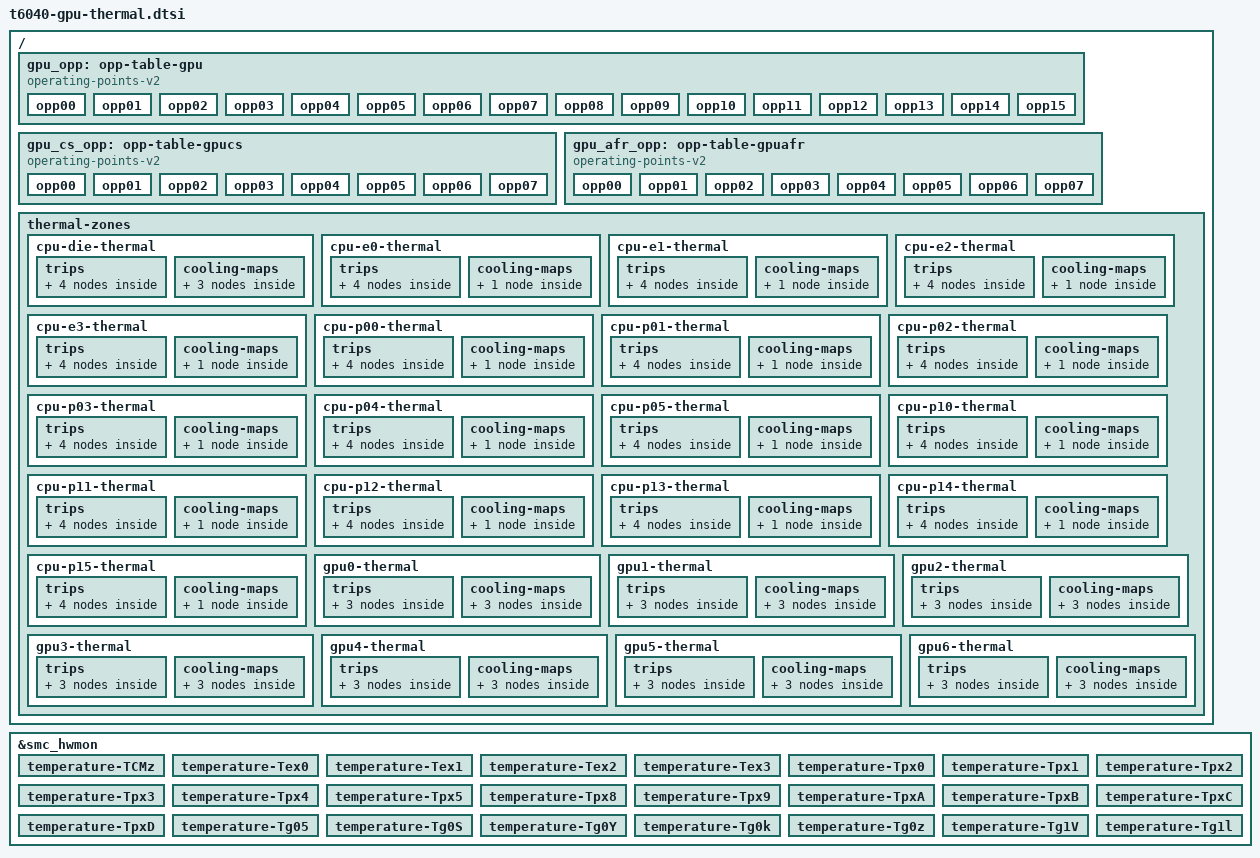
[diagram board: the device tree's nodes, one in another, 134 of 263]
// SPDX-License-Identifier: GPL-2.0+ OR MIT
/*
 * GPU operating points and thermal zones of the T6040 Macs, with the SMC
 * sensors the zones read. Shared by the J614s, J616s and J773s.
 *
 * Copyright The Asahi Linux Contributors
 */

#include <dt-bindings/thermal/thermal.h>

/ {
	/*
	 * GPU performance states, one opp-microvolt cell per cluster (ADT
	 * /arm-io/sgx perf-states and perf-states1). The operating points are
	 * binned per device: the loader fills these placeholders.
	 * The driver requires a completed calibration handoff. Entries keep the
	 * order of the GPU performance states, which is not sorted by frequency.
	 */
	gpu_opp: opp-table-gpu {
		compatible = "operating-points-v2";

		opp00 {
			opp-hz = /bits/ 64 <0>;
			opp-microvolt = <0 0>;
		};
		opp01 {
			opp-hz = /bits/ 64 <0>;
			opp-microvolt = <0 0>;
		};
		opp02 {
			opp-hz = /bits/ 64 <0>;
			opp-microvolt = <0 0>;
		};
		opp03 {
			opp-hz = /bits/ 64 <0>;
			opp-microvolt = <0 0>;
		};
		opp04 {
			opp-hz = /bits/ 64 <0>;
			opp-microvolt = <0 0>;
		};
		opp05 {
			opp-hz = /bits/ 64 <0>;
			opp-microvolt = <0 0>;
		};
		opp06 {
			opp-hz = /bits/ 64 <0>;
			opp-microvolt = <0 0>;
		};
		opp07 {
			opp-hz = /bits/ 64 <0>;
			opp-microvolt = <0 0>;
		};
		opp08 {
			opp-hz = /bits/ 64 <0>;
			opp-microvolt = <0 0>;
		};
		opp09 {
			opp-hz = /bits/ 64 <0>;
			opp-microvolt = <0 0>;
		};
		opp10 {
			opp-hz = /bits/ 64 <0>;
			opp-microvolt = <0 0>;
		};
		opp11 {
			opp-hz = /bits/ 64 <0>;
			opp-microvolt = <0 0>;
		};
		opp12 {
			opp-hz = /bits/ 64 <0>;
			opp-microvolt = <0 0>;
		};
		opp13 {
			opp-hz = /bits/ 64 <0>;
			opp-microvolt = <0 0>;
		};
		opp14 {
			opp-hz = /bits/ 64 <0>;
			opp-microvolt = <0 0>;
		};
		opp15 {
			opp-hz = /bits/ 64 <0>;
			opp-microvolt = <0 0>;
		};
	};

	/* The GPU's CS clock domain (ADT cs-perf-states) */
	gpu_cs_opp: opp-table-gpucs {
		compatible = "operating-points-v2";

		opp00 {
			opp-hz = /bits/ 64 <0>;
			opp-microvolt = <0>;
		};
		opp01 {
			opp-hz = /bits/ 64 <0>;
			opp-microvolt = <0>;
		};
		opp02 {
			opp-hz = /bits/ 64 <0>;
			opp-microvolt = <0>;
		};
		opp03 {
			opp-hz = /bits/ 64 <0>;
			opp-microvolt = <0>;
		};
		opp04 {
			opp-hz = /bits/ 64 <0>;
			opp-microvolt = <0>;
		};
		opp05 {
			opp-hz = /bits/ 64 <0>;
			opp-microvolt = <0>;
		};
		opp06 {
			opp-hz = /bits/ 64 <0>;
			opp-microvolt = <0>;
		};
		opp07 {
			opp-hz = /bits/ 64 <0>;
			opp-microvolt = <0>;
		};
	};

	/* The GPU's AFR clock domain (ADT afr-perf-states) */
	gpu_afr_opp: opp-table-gpuafr {
		compatible = "operating-points-v2";

		opp00 {
			opp-hz = /bits/ 64 <0>;
			opp-microvolt = <0>;
		};
		opp01 {
			opp-hz = /bits/ 64 <0>;
			opp-microvolt = <0>;
		};
		opp02 {
			opp-hz = /bits/ 64 <0>;
			opp-microvolt = <0>;
		};
		opp03 {
			opp-hz = /bits/ 64 <0>;
			opp-microvolt = <0>;
		};
		opp04 {
			opp-hz = /bits/ 64 <0>;
			opp-microvolt = <0>;
		};
		opp05 {
			opp-hz = /bits/ 64 <0>;
			opp-microvolt = <0>;
		};
		opp06 {
			opp-hz = /bits/ 64 <0>;
			opp-microvolt = <0>;
		};
		opp07 {
			opp-hz = /bits/ 64 <0>;
			opp-microvolt = <0>;
		};
	};

	/*
	 * Zones on the SMC die-maximum sensors (smc_hwmon 0-23): TCMz for the
	 * die, Tex0-3, Tpx0-5 and Tpx8-D per CPU cluster, and the seven
	 * hottest GPU sensors. The PMP's loop holds the die at the ADT
	 * fast-die-ctrl-loop target of 110 C, as on macOS; these zones are
	 * the backstop behind it.
	 *
	 * - CPU zones run the power allocator from 75 C, control at 115 C and
	 *   throttle only the cluster their sensor sits on. The 1 s samples
	 *   jump by about 10 C, so the zones are integral-led.
	 * - GPU zones: the GPU firmware limits itself from 101 C; these shed
	 *   CPU power from the same point (on at 90 C) and shut down at 118 C
	 *   after three samples, as the CPU zones do. A powered-off GPU reads
	 *   -4 to 4 C.
	 * - Hot at 120 C only reports; critical is the ADT's 125 C sochot
	 *   level, after three samples (critical-samples).
	 * - The fans stay with the SMC, as on macOS: no active trips.
	 *
	 * sustainable-power is the J616s's: a 720 s all-core load held TCMz
	 * at 112-114 C with P0 25.3 W, P1 23.9 W and E 2.1 W on the SMC core
	 * rails. The J614s and J773s inherit these values until measured.
	 */
	thermal-zones {
		cpu-die-thermal {
			polling-delay-passive = <1000>;
			polling-delay = <1000>;
			integral-time-constant-ms = <20000>;
			critical-samples = <3>;
			sustainable-power = <51300>;
			thermal-sensors = <&smc_hwmon 0>;	/* TCMz */

			trips {
				cpu_die_switch_on: cpu-die-switch-on {
					temperature = <75000>;
					hysteresis = <2000>;
					type = "passive";
				};

				cpu_die_passive: cpu-die-passive {
					temperature = <115000>;
					hysteresis = <5000>;
					type = "passive";
				};

				cpu-die-hot {
					temperature = <120000>;
					hysteresis = <2000>;
					type = "hot";
				};

				cpu-die-critical {
					temperature = <125000>;
					hysteresis = <0>;
					type = "critical";
				};
			};

			cooling-maps {
				map-e {
					trip = <&cpu_die_passive>;
					cooling-device =
						<&cpu_e0 THERMAL_NO_LIMIT THERMAL_NO_LIMIT>,
						<&cpu_e1 THERMAL_NO_LIMIT THERMAL_NO_LIMIT>,
						<&cpu_e2 THERMAL_NO_LIMIT THERMAL_NO_LIMIT>,
						<&cpu_e3 THERMAL_NO_LIMIT THERMAL_NO_LIMIT>;
				};

				map-p0 {
					trip = <&cpu_die_passive>;
					cooling-device =
						<&cpu_p00 THERMAL_NO_LIMIT THERMAL_NO_LIMIT>,
						<&cpu_p01 THERMAL_NO_LIMIT THERMAL_NO_LIMIT>,
						<&cpu_p02 THERMAL_NO_LIMIT THERMAL_NO_LIMIT>,
						<&cpu_p03 THERMAL_NO_LIMIT THERMAL_NO_LIMIT>,
						<&cpu_p04 THERMAL_NO_LIMIT THERMAL_NO_LIMIT>;
				};

				map-p1 {
					trip = <&cpu_die_passive>;
					cooling-device =
						<&cpu_p10 THERMAL_NO_LIMIT THERMAL_NO_LIMIT>,
						<&cpu_p11 THERMAL_NO_LIMIT THERMAL_NO_LIMIT>,
						<&cpu_p12 THERMAL_NO_LIMIT THERMAL_NO_LIMIT>,
						<&cpu_p13 THERMAL_NO_LIMIT THERMAL_NO_LIMIT>,
						<&cpu_p14 THERMAL_NO_LIMIT THERMAL_NO_LIMIT>;
				};
			};
		};

		cpu-e0-thermal {
			polling-delay-passive = <1000>;
			polling-delay = <1000>;
			integral-time-constant-ms = <20000>;
			critical-samples = <3>;
			sustainable-power = <2100>;
			thermal-sensors = <&smc_hwmon 1>;	/* Tex0 */

			trips {
				cpu_e0_switch_on: trip-switch-on {
					temperature = <75000>;
					hysteresis = <2000>;
					type = "passive";
				};

				cpu_e0_passive: trip-passive {
					temperature = <115000>;
					hysteresis = <5000>;
					type = "passive";
				};

				trip-hot {
					temperature = <120000>;
					hysteresis = <2000>;
					type = "hot";
				};

				trip-critical {
					temperature = <125000>;
					hysteresis = <0>;
					type = "critical";
				};
			};

			cooling-maps {
				map-e {
					trip = <&cpu_e0_passive>;
					cooling-device =
						<&cpu_e0 THERMAL_NO_LIMIT THERMAL_NO_LIMIT>,
						<&cpu_e1 THERMAL_NO_LIMIT THERMAL_NO_LIMIT>,
						<&cpu_e2 THERMAL_NO_LIMIT THERMAL_NO_LIMIT>,
						<&cpu_e3 THERMAL_NO_LIMIT THERMAL_NO_LIMIT>;
				};
			};
		};

		cpu-e1-thermal {
			polling-delay-passive = <1000>;
			polling-delay = <1000>;
			integral-time-constant-ms = <20000>;
			critical-samples = <3>;
			sustainable-power = <2100>;
			thermal-sensors = <&smc_hwmon 2>;	/* Tex1 */

			trips {
				cpu_e1_switch_on: trip-switch-on {
					temperature = <75000>;
					hysteresis = <2000>;
					type = "passive";
				};

				cpu_e1_passive: trip-passive {
					temperature = <115000>;
					hysteresis = <5000>;
					type = "passive";
				};

				trip-hot {
					temperature = <120000>;
					hysteresis = <2000>;
					type = "hot";
				};

				trip-critical {
					temperature = <125000>;
					hysteresis = <0>;
					type = "critical";
				};
			};

			cooling-maps {
				map-e {
					trip = <&cpu_e1_passive>;
					cooling-device =
						<&cpu_e0 THERMAL_NO_LIMIT THERMAL_NO_LIMIT>,
						<&cpu_e1 THERMAL_NO_LIMIT THERMAL_NO_LIMIT>,
						<&cpu_e2 THERMAL_NO_LIMIT THERMAL_NO_LIMIT>,
						<&cpu_e3 THERMAL_NO_LIMIT THERMAL_NO_LIMIT>;
				};
			};
		};

		cpu-e2-thermal {
			polling-delay-passive = <1000>;
			polling-delay = <1000>;
			integral-time-constant-ms = <20000>;
			critical-samples = <3>;
			sustainable-power = <2100>;
			thermal-sensors = <&smc_hwmon 3>;	/* Tex2 */

			trips {
				cpu_e2_switch_on: trip-switch-on {
					temperature = <75000>;
					hysteresis = <2000>;
					type = "passive";
				};

				cpu_e2_passive: trip-passive {
					temperature = <115000>;
					hysteresis = <5000>;
					type = "passive";
				};

				trip-hot {
					temperature = <120000>;
					hysteresis = <2000>;
					type = "hot";
				};

				trip-critical {
					temperature = <125000>;
					hysteresis = <0>;
					type = "critical";
				};
			};

			cooling-maps {
				map-e {
					trip = <&cpu_e2_passive>;
					cooling-device =
						<&cpu_e0 THERMAL_NO_LIMIT THERMAL_NO_LIMIT>,
						<&cpu_e1 THERMAL_NO_LIMIT THERMAL_NO_LIMIT>,
						<&cpu_e2 THERMAL_NO_LIMIT THERMAL_NO_LIMIT>,
						<&cpu_e3 THERMAL_NO_LIMIT THERMAL_NO_LIMIT>;
				};
			};
		};

		cpu-e3-thermal {
			polling-delay-passive = <1000>;
			polling-delay = <1000>;
			integral-time-constant-ms = <20000>;
			critical-samples = <3>;
			sustainable-power = <2100>;
			thermal-sensors = <&smc_hwmon 4>;	/* Tex3 */

			trips {
				cpu_e3_switch_on: trip-switch-on {
					temperature = <75000>;
					hysteresis = <2000>;
					type = "passive";
				};

				cpu_e3_passive: trip-passive {
					temperature = <115000>;
					hysteresis = <5000>;
					type = "passive";
				};

				trip-hot {
					temperature = <120000>;
					hysteresis = <2000>;
					type = "hot";
				};

				trip-critical {
					temperature = <125000>;
					hysteresis = <0>;
					type = "critical";
				};
			};

			cooling-maps {
				map-e {
					trip = <&cpu_e3_passive>;
					cooling-device =
						<&cpu_e0 THERMAL_NO_LIMIT THERMAL_NO_LIMIT>,
						<&cpu_e1 THERMAL_NO_LIMIT THERMAL_NO_LIMIT>,
						<&cpu_e2 THERMAL_NO_LIMIT THERMAL_NO_LIMIT>,
						<&cpu_e3 THERMAL_NO_LIMIT THERMAL_NO_LIMIT>;
				};
			};
		};

		cpu-p00-thermal {
			polling-delay-passive = <1000>;
			polling-delay = <1000>;
			integral-time-constant-ms = <20000>;
			critical-samples = <3>;
			sustainable-power = <25300>;
			thermal-sensors = <&smc_hwmon 5>;	/* Tpx0 */

			trips {
				cpu_p00_switch_on: trip-switch-on {
					temperature = <75000>;
					hysteresis = <2000>;
					type = "passive";
				};

				cpu_p00_passive: trip-passive {
					temperature = <115000>;
					hysteresis = <5000>;
					type = "passive";
				};

				trip-hot {
					temperature = <120000>;
					hysteresis = <2000>;
					type = "hot";
				};

				trip-critical {
					temperature = <125000>;
					hysteresis = <0>;
					type = "critical";
				};
			};

			cooling-maps {
				map-p0 {
					trip = <&cpu_p00_passive>;
					cooling-device =
						<&cpu_p00 THERMAL_NO_LIMIT THERMAL_NO_LIMIT>,
						<&cpu_p01 THERMAL_NO_LIMIT THERMAL_NO_LIMIT>,
						<&cpu_p02 THERMAL_NO_LIMIT THERMAL_NO_LIMIT>,
						<&cpu_p03 THERMAL_NO_LIMIT THERMAL_NO_LIMIT>,
						<&cpu_p04 THERMAL_NO_LIMIT THERMAL_NO_LIMIT>;
				};
			};
		};

		cpu-p01-thermal {
			polling-delay-passive = <1000>;
			polling-delay = <1000>;
			integral-time-constant-ms = <20000>;
			critical-samples = <3>;
			sustainable-power = <25300>;
			thermal-sensors = <&smc_hwmon 6>;	/* Tpx1 */

			trips {
				cpu_p01_switch_on: trip-switch-on {
					temperature = <75000>;
					hysteresis = <2000>;
					type = "passive";
				};

				cpu_p01_passive: trip-passive {
					temperature = <115000>;
					hysteresis = <5000>;
					type = "passive";
				};

				trip-hot {
					temperature = <120000>;
					hysteresis = <2000>;
					type = "hot";
				};

				trip-critical {
					temperature = <125000>;
					hysteresis = <0>;
					type = "critical";
				};
			};

			cooling-maps {
				map-p0 {
					trip = <&cpu_p01_passive>;
					cooling-device =
						<&cpu_p00 THERMAL_NO_LIMIT THERMAL_NO_LIMIT>,
						<&cpu_p01 THERMAL_NO_LIMIT THERMAL_NO_LIMIT>,
						<&cpu_p02 THERMAL_NO_LIMIT THERMAL_NO_LIMIT>,
						<&cpu_p03 THERMAL_NO_LIMIT THERMAL_NO_LIMIT>,
						<&cpu_p04 THERMAL_NO_LIMIT THERMAL_NO_LIMIT>;
				};
			};
		};

		cpu-p02-thermal {
			polling-delay-passive = <1000>;
			polling-delay = <1000>;
			integral-time-constant-ms = <20000>;
			critical-samples = <3>;
			sustainable-power = <25300>;
			thermal-sensors = <&smc_hwmon 7>;	/* Tpx2 */

			trips {
				cpu_p02_switch_on: trip-switch-on {
					temperature = <75000>;
					hysteresis = <2000>;
					type = "passive";
				};

				cpu_p02_passive: trip-passive {
					temperature = <115000>;
					hysteresis = <5000>;
					type = "passive";
				};

				trip-hot {
					temperature = <120000>;
					hysteresis = <2000>;
					type = "hot";
				};

				trip-critical {
					temperature = <125000>;
					hysteresis = <0>;
					type = "critical";
				};
			};

			cooling-maps {
				map-p0 {
					trip = <&cpu_p02_passive>;
					cooling-device =
						<&cpu_p00 THERMAL_NO_LIMIT THERMAL_NO_LIMIT>,
						<&cpu_p01 THERMAL_NO_LIMIT THERMAL_NO_LIMIT>,
						<&cpu_p02 THERMAL_NO_LIMIT THERMAL_NO_LIMIT>,
						<&cpu_p03 THERMAL_NO_LIMIT THERMAL_NO_LIMIT>,
						<&cpu_p04 THERMAL_NO_LIMIT THERMAL_NO_LIMIT>;
				};
			};
		};

		cpu-p03-thermal {
			polling-delay-passive = <1000>;
			polling-delay = <1000>;
			integral-time-constant-ms = <20000>;
			critical-samples = <3>;
			sustainable-power = <25300>;
			thermal-sensors = <&smc_hwmon 8>;	/* Tpx3 */

			trips {
				cpu_p03_switch_on: trip-switch-on {
					temperature = <75000>;
					hysteresis = <2000>;
					type = "passive";
				};

				cpu_p03_passive: trip-passive {
					temperature = <115000>;
					hysteresis = <5000>;
					type = "passive";
				};

				trip-hot {
					temperature = <120000>;
					hysteresis = <2000>;
					type = "hot";
				};

				trip-critical {
					temperature = <125000>;
					hysteresis = <0>;
					type = "critical";
				};
			};

			cooling-maps {
				map-p0 {
					trip = <&cpu_p03_passive>;
					cooling-device =
						<&cpu_p00 THERMAL_NO_LIMIT THERMAL_NO_LIMIT>,
						<&cpu_p01 THERMAL_NO_LIMIT THERMAL_NO_LIMIT>,
						<&cpu_p02 THERMAL_NO_LIMIT THERMAL_NO_LIMIT>,
						<&cpu_p03 THERMAL_NO_LIMIT THERMAL_NO_LIMIT>,
						<&cpu_p04 THERMAL_NO_LIMIT THERMAL_NO_LIMIT>;
				};
			};
		};

		cpu-p04-thermal {
			polling-delay-passive = <1000>;
			polling-delay = <1000>;
			integral-time-constant-ms = <20000>;
			critical-samples = <3>;
			sustainable-power = <25300>;
			thermal-sensors = <&smc_hwmon 9>;	/* Tpx4 */

			trips {
				cpu_p04_switch_on: trip-switch-on {
					temperature = <75000>;
					hysteresis = <2000>;
					type = "passive";
				};

				cpu_p04_passive: trip-passive {
					temperature = <115000>;
					hysteresis = <5000>;
					type = "passive";
				};

				trip-hot {
					temperature = <120000>;
					hysteresis = <2000>;
					type = "hot";
				};

				trip-critical {
					temperature = <125000>;
					hysteresis = <0>;
					type = "critical";
				};
			};

			cooling-maps {
				map-p0 {
					trip = <&cpu_p04_passive>;
					cooling-device =
						<&cpu_p00 THERMAL_NO_LIMIT THERMAL_NO_LIMIT>,
						<&cpu_p01 THERMAL_NO_LIMIT THERMAL_NO_LIMIT>,
						<&cpu_p02 THERMAL_NO_LIMIT THERMAL_NO_LIMIT>,
						<&cpu_p03 THERMAL_NO_LIMIT THERMAL_NO_LIMIT>,
						<&cpu_p04 THERMAL_NO_LIMIT THERMAL_NO_LIMIT>;
				};
			};
		};

		cpu-p05-thermal {
			polling-delay-passive = <1000>;
			polling-delay = <1000>;
			integral-time-constant-ms = <20000>;
			critical-samples = <3>;
			sustainable-power = <25300>;
			thermal-sensors = <&smc_hwmon 10>;	/* Tpx5 */

			trips {
				cpu_p05_switch_on: trip-switch-on {
					temperature = <75000>;
					hysteresis = <2000>;
					type = "passive";
				};

				cpu_p05_passive: trip-passive {
					temperature = <115000>;
					hysteresis = <5000>;
					type = "passive";
				};

				trip-hot {
					temperature = <120000>;
					hysteresis = <2000>;
					type = "hot";
				};

				trip-critical {
					temperature = <125000>;
					hysteresis = <0>;
					type = "critical";
				};
			};

			cooling-maps {
				map-p0 {
					trip = <&cpu_p05_passive>;
					cooling-device =
						<&cpu_p00 THERMAL_NO_LIMIT THERMAL_NO_LIMIT>,
						<&cpu_p01 THERMAL_NO_LIMIT THERMAL_NO_LIMIT>,
						<&cpu_p02 THERMAL_NO_LIMIT THERMAL_NO_LIMIT>,
						<&cpu_p03 THERMAL_NO_LIMIT THERMAL_NO_LIMIT>,
						<&cpu_p04 THERMAL_NO_LIMIT THERMAL_NO_LIMIT>;
				};
			};
		};

		cpu-p10-thermal {
			polling-delay-passive = <1000>;
			polling-delay = <1000>;
			integral-time-constant-ms = <20000>;
			critical-samples = <3>;
			sustainable-power = <23900>;
			thermal-sensors = <&smc_hwmon 11>;	/* Tpx8 */

			trips {
				cpu_p10_switch_on: trip-switch-on {
					temperature = <75000>;
					hysteresis = <2000>;
					type = "passive";
				};

				cpu_p10_passive: trip-passive {
					temperature = <115000>;
					hysteresis = <5000>;
					type = "passive";
				};

				trip-hot {
					temperature = <120000>;
					hysteresis = <2000>;
					type = "hot";
				};

				trip-critical {
					temperature = <125000>;
					hysteresis = <0>;
					type = "critical";
				};
			};

			cooling-maps {
				map-p1 {
					trip = <&cpu_p10_passive>;
					cooling-device =
						<&cpu_p10 THERMAL_NO_LIMIT THERMAL_NO_LIMIT>,
						<&cpu_p11 THERMAL_NO_LIMIT THERMAL_NO_LIMIT>,
						<&cpu_p12 THERMAL_NO_LIMIT THERMAL_NO_LIMIT>,
						<&cpu_p13 THERMAL_NO_LIMIT THERMAL_NO_LIMIT>,
						<&cpu_p14 THERMAL_NO_LIMIT THERMAL_NO_LIMIT>;
				};
			};
		};

		cpu-p11-thermal {
			polling-delay-passive = <1000>;
			polling-delay = <1000>;
			integral-time-constant-ms = <20000>;
			critical-samples = <3>;
			sustainable-power = <23900>;
			thermal-sensors = <&smc_hwmon 12>;	/* Tpx9 */

			trips {
				cpu_p11_switch_on: trip-switch-on {
					temperature = <75000>;
					hysteresis = <2000>;
					type = "passive";
				};

				cpu_p11_passive: trip-passive {
					temperature = <115000>;
					hysteresis = <5000>;
					type = "passive";
				};

				trip-hot {
					temperature = <120000>;
					hysteresis = <2000>;
					type = "hot";
				};

				trip-critical {
					temperature = <125000>;
					hysteresis = <0>;
					type = "critical";
				};
			};

			cooling-maps {
				map-p1 {
					trip = <&cpu_p11_passive>;
					cooling-device =
						<&cpu_p10 THERMAL_NO_LIMIT THERMAL_NO_LIMIT>,
						<&cpu_p11 THERMAL_NO_LIMIT THERMAL_NO_LIMIT>,
						<&cpu_p12 THERMAL_NO_LIMIT THERMAL_NO_LIMIT>,
						<&cpu_p13 THERMAL_NO_LIMIT THERMAL_NO_LIMIT>,
						<&cpu_p14 THERMAL_NO_LIMIT THERMAL_NO_LIMIT>;
				};
			};
		};

		cpu-p12-thermal {
			polling-delay-passive = <1000>;
			polling-delay = <1000>;
			integral-time-constant-ms = <20000>;
			critical-samples = <3>;
			sustainable-power = <23900>;
			thermal-sensors = <&smc_hwmon 13>;	/* TpxA */

			trips {
				cpu_p12_switch_on: trip-switch-on {
					temperature = <75000>;
					hysteresis = <2000>;
					type = "passive";
				};

				cpu_p12_passive: trip-passive {
					temperature = <115000>;
					hysteresis = <5000>;
					type = "passive";
				};

				trip-hot {
					temperature = <120000>;
					hysteresis = <2000>;
					type = "hot";
				};

				trip-critical {
					temperature = <125000>;
					hysteresis = <0>;
					type = "critical";
				};
			};

			cooling-maps {
				map-p1 {
					trip = <&cpu_p12_passive>;
					cooling-device =
						<&cpu_p10 THERMAL_NO_LIMIT THERMAL_NO_LIMIT>,
						<&cpu_p11 THERMAL_NO_LIMIT THERMAL_NO_LIMIT>,
						<&cpu_p12 THERMAL_NO_LIMIT THERMAL_NO_LIMIT>,
						<&cpu_p13 THERMAL_NO_LIMIT THERMAL_NO_LIMIT>,
						<&cpu_p14 THERMAL_NO_LIMIT THERMAL_NO_LIMIT>;
				};
			};
		};

		cpu-p13-thermal {
			polling-delay-passive = <1000>;
			polling-delay = <1000>;
			integral-time-constant-ms = <20000>;
			critical-samples = <3>;
			sustainable-power = <23900>;
			thermal-sensors = <&smc_hwmon 14>;	/* TpxB */

			trips {
				cpu_p13_switch_on: trip-switch-on {
					temperature = <75000>;
					hysteresis = <2000>;
					type = "passive";
				};

				cpu_p13_passive: trip-passive {
					temperature = <115000>;
					hysteresis = <5000>;
					type = "passive";
				};

				trip-hot {
					temperature = <120000>;
					hysteresis = <2000>;
					type = "hot";
				};

				trip-critical {
					temperature = <125000>;
					hysteresis = <0>;
					type = "critical";
				};
			};

			cooling-maps {
				map-p1 {
					trip = <&cpu_p13_passive>;
					cooling-device =
						<&cpu_p10 THERMAL_NO_LIMIT THERMAL_NO_LIMIT>,
						<&cpu_p11 THERMAL_NO_LIMIT THERMAL_NO_LIMIT>,
						<&cpu_p12 THERMAL_NO_LIMIT THERMAL_NO_LIMIT>,
						<&cpu_p13 THERMAL_NO_LIMIT THERMAL_NO_LIMIT>,
						<&cpu_p14 THERMAL_NO_LIMIT THERMAL_NO_LIMIT>;
				};
			};
		};

		cpu-p14-thermal {
			polling-delay-passive = <1000>;
			polling-delay = <1000>;
			integral-time-constant-ms = <20000>;
			critical-samples = <3>;
			sustainable-power = <23900>;
			thermal-sensors = <&smc_hwmon 15>;	/* TpxC */

			trips {
				cpu_p14_switch_on: trip-switch-on {
					temperature = <75000>;
					hysteresis = <2000>;
					type = "passive";
				};

				cpu_p14_passive: trip-passive {
					temperature = <115000>;
					hysteresis = <5000>;
					type = "passive";
				};

				trip-hot {
					temperature = <120000>;
					hysteresis = <2000>;
					type = "hot";
				};

				trip-critical {
					temperature = <125000>;
					hysteresis = <0>;
					type = "critical";
				};
			};

			cooling-maps {
				map-p1 {
					trip = <&cpu_p14_passive>;
					cooling-device =
						<&cpu_p10 THERMAL_NO_LIMIT THERMAL_NO_LIMIT>,
						<&cpu_p11 THERMAL_NO_LIMIT THERMAL_NO_LIMIT>,
						<&cpu_p12 THERMAL_NO_LIMIT THERMAL_NO_LIMIT>,
						<&cpu_p13 THERMAL_NO_LIMIT THERMAL_NO_LIMIT>,
						<&cpu_p14 THERMAL_NO_LIMIT THERMAL_NO_LIMIT>;
				};
			};
		};

		cpu-p15-thermal {
			polling-delay-passive = <1000>;
			polling-delay = <1000>;
			integral-time-constant-ms = <20000>;
			critical-samples = <3>;
			sustainable-power = <23900>;
			thermal-sensors = <&smc_hwmon 16>;	/* TpxD */

			trips {
				cpu_p15_switch_on: trip-switch-on {
					temperature = <75000>;
					hysteresis = <2000>;
					type = "passive";
				};

				cpu_p15_passive: trip-passive {
					temperature = <115000>;
					hysteresis = <5000>;
					type = "passive";
				};

				trip-hot {
					temperature = <120000>;
					hysteresis = <2000>;
					type = "hot";
				};

				trip-critical {
					temperature = <125000>;
					hysteresis = <0>;
					type = "critical";
				};
			};

			cooling-maps {
				map-p1 {
					trip = <&cpu_p15_passive>;
					cooling-device =
						<&cpu_p10 THERMAL_NO_LIMIT THERMAL_NO_LIMIT>,
						<&cpu_p11 THERMAL_NO_LIMIT THERMAL_NO_LIMIT>,
						<&cpu_p12 THERMAL_NO_LIMIT THERMAL_NO_LIMIT>,
						<&cpu_p13 THERMAL_NO_LIMIT THERMAL_NO_LIMIT>,
						<&cpu_p14 THERMAL_NO_LIMIT THERMAL_NO_LIMIT>;
				};
			};
		};

		gpu0-thermal {
			polling-delay-passive = <1000>;
			polling-delay = <1000>;
			critical-samples = <3>;
			sustainable-power = <51300>;
			thermal-sensors = <&smc_hwmon 17>;	/* Tg05 */

			trips {
				gpu0_switch_on: trip-switch-on {
					temperature = <90000>;
					hysteresis = <2000>;
					type = "passive";
				};

				gpu0_passive: trip-passive {
					temperature = <101000>;
					hysteresis = <5000>;
					type = "passive";
				};

				trip-critical {
					temperature = <118000>;
					hysteresis = <0>;
					type = "critical";
				};
			};

			cooling-maps {
				map-e {
					trip = <&gpu0_passive>;
					cooling-device =
						<&cpu_e0 THERMAL_NO_LIMIT THERMAL_NO_LIMIT>,
						<&cpu_e1 THERMAL_NO_LIMIT THERMAL_NO_LIMIT>,
						<&cpu_e2 THERMAL_NO_LIMIT THERMAL_NO_LIMIT>,
						<&cpu_e3 THERMAL_NO_LIMIT THERMAL_NO_LIMIT>;
				};

				map-p0 {
					trip = <&gpu0_passive>;
					cooling-device =
						<&cpu_p00 THERMAL_NO_LIMIT THERMAL_NO_LIMIT>,
						<&cpu_p01 THERMAL_NO_LIMIT THERMAL_NO_LIMIT>,
						<&cpu_p02 THERMAL_NO_LIMIT THERMAL_NO_LIMIT>,
						<&cpu_p03 THERMAL_NO_LIMIT THERMAL_NO_LIMIT>,
						<&cpu_p04 THERMAL_NO_LIMIT THERMAL_NO_LIMIT>;
				};

				map-p1 {
					trip = <&gpu0_passive>;
					cooling-device =
						<&cpu_p10 THERMAL_NO_LIMIT THERMAL_NO_LIMIT>,
						<&cpu_p11 THERMAL_NO_LIMIT THERMAL_NO_LIMIT>,
						<&cpu_p12 THERMAL_NO_LIMIT THERMAL_NO_LIMIT>,
						<&cpu_p13 THERMAL_NO_LIMIT THERMAL_NO_LIMIT>,
						<&cpu_p14 THERMAL_NO_LIMIT THERMAL_NO_LIMIT>;
				};
			};
		};

		gpu1-thermal {
			polling-delay-passive = <1000>;
			polling-delay = <1000>;
			critical-samples = <3>;
			sustainable-power = <51300>;
			thermal-sensors = <&smc_hwmon 18>;	/* Tg0S */

			trips {
				gpu1_switch_on: trip-switch-on {
					temperature = <90000>;
					hysteresis = <2000>;
					type = "passive";
				};

				gpu1_passive: trip-passive {
					temperature = <101000>;
					hysteresis = <5000>;
					type = "passive";
				};

				trip-critical {
					temperature = <118000>;
					hysteresis = <0>;
					type = "critical";
				};
			};

			cooling-maps {
				map-e {
					trip = <&gpu1_passive>;
					cooling-device =
						<&cpu_e0 THERMAL_NO_LIMIT THERMAL_NO_LIMIT>,
						<&cpu_e1 THERMAL_NO_LIMIT THERMAL_NO_LIMIT>,
						<&cpu_e2 THERMAL_NO_LIMIT THERMAL_NO_LIMIT>,
						<&cpu_e3 THERMAL_NO_LIMIT THERMAL_NO_LIMIT>;
				};

				map-p0 {
					trip = <&gpu1_passive>;
					cooling-device =
						<&cpu_p00 THERMAL_NO_LIMIT THERMAL_NO_LIMIT>,
						<&cpu_p01 THERMAL_NO_LIMIT THERMAL_NO_LIMIT>,
						<&cpu_p02 THERMAL_NO_LIMIT THERMAL_NO_LIMIT>,
						<&cpu_p03 THERMAL_NO_LIMIT THERMAL_NO_LIMIT>,
						<&cpu_p04 THERMAL_NO_LIMIT THERMAL_NO_LIMIT>;
				};

				map-p1 {
					trip = <&gpu1_passive>;
					cooling-device =
						<&cpu_p10 THERMAL_NO_LIMIT THERMAL_NO_LIMIT>,
						<&cpu_p11 THERMAL_NO_LIMIT THERMAL_NO_LIMIT>,
						<&cpu_p12 THERMAL_NO_LIMIT THERMAL_NO_LIMIT>,
						<&cpu_p13 THERMAL_NO_LIMIT THERMAL_NO_LIMIT>,
						<&cpu_p14 THERMAL_NO_LIMIT THERMAL_NO_LIMIT>;
				};
			};
		};

		gpu2-thermal {
			polling-delay-passive = <1000>;
			polling-delay = <1000>;
			critical-samples = <3>;
			sustainable-power = <51300>;
			thermal-sensors = <&smc_hwmon 19>;	/* Tg0Y */

			trips {
				gpu2_switch_on: trip-switch-on {
					temperature = <90000>;
					hysteresis = <2000>;
					type = "passive";
				};

				gpu2_passive: trip-passive {
					temperature = <101000>;
					hysteresis = <5000>;
					type = "passive";
				};

				trip-critical {
					temperature = <118000>;
					hysteresis = <0>;
					type = "critical";
				};
			};

			cooling-maps {
				map-e {
					trip = <&gpu2_passive>;
					cooling-device =
						<&cpu_e0 THERMAL_NO_LIMIT THERMAL_NO_LIMIT>,
						<&cpu_e1 THERMAL_NO_LIMIT THERMAL_NO_LIMIT>,
						<&cpu_e2 THERMAL_NO_LIMIT THERMAL_NO_LIMIT>,
						<&cpu_e3 THERMAL_NO_LIMIT THERMAL_NO_LIMIT>;
				};

				map-p0 {
					trip = <&gpu2_passive>;
					cooling-device =
						<&cpu_p00 THERMAL_NO_LIMIT THERMAL_NO_LIMIT>,
						<&cpu_p01 THERMAL_NO_LIMIT THERMAL_NO_LIMIT>,
						<&cpu_p02 THERMAL_NO_LIMIT THERMAL_NO_LIMIT>,
						<&cpu_p03 THERMAL_NO_LIMIT THERMAL_NO_LIMIT>,
						<&cpu_p04 THERMAL_NO_LIMIT THERMAL_NO_LIMIT>;
				};

				map-p1 {
					trip = <&gpu2_passive>;
					cooling-device =
						<&cpu_p10 THERMAL_NO_LIMIT THERMAL_NO_LIMIT>,
						<&cpu_p11 THERMAL_NO_LIMIT THERMAL_NO_LIMIT>,
						<&cpu_p12 THERMAL_NO_LIMIT THERMAL_NO_LIMIT>,
						<&cpu_p13 THERMAL_NO_LIMIT THERMAL_NO_LIMIT>,
						<&cpu_p14 THERMAL_NO_LIMIT THERMAL_NO_LIMIT>;
				};
			};
		};

		gpu3-thermal {
			polling-delay-passive = <1000>;
			polling-delay = <1000>;
			critical-samples = <3>;
			sustainable-power = <51300>;
			thermal-sensors = <&smc_hwmon 20>;	/* Tg0k */

			trips {
				gpu3_switch_on: trip-switch-on {
					temperature = <90000>;
					hysteresis = <2000>;
					type = "passive";
				};

				gpu3_passive: trip-passive {
					temperature = <101000>;
					hysteresis = <5000>;
					type = "passive";
				};

				trip-critical {
					temperature = <118000>;
					hysteresis = <0>;
					type = "critical";
				};
			};

			cooling-maps {
				map-e {
					trip = <&gpu3_passive>;
					cooling-device =
						<&cpu_e0 THERMAL_NO_LIMIT THERMAL_NO_LIMIT>,
						<&cpu_e1 THERMAL_NO_LIMIT THERMAL_NO_LIMIT>,
						<&cpu_e2 THERMAL_NO_LIMIT THERMAL_NO_LIMIT>,
						<&cpu_e3 THERMAL_NO_LIMIT THERMAL_NO_LIMIT>;
				};

				map-p0 {
					trip = <&gpu3_passive>;
					cooling-device =
						<&cpu_p00 THERMAL_NO_LIMIT THERMAL_NO_LIMIT>,
						<&cpu_p01 THERMAL_NO_LIMIT THERMAL_NO_LIMIT>,
						<&cpu_p02 THERMAL_NO_LIMIT THERMAL_NO_LIMIT>,
						<&cpu_p03 THERMAL_NO_LIMIT THERMAL_NO_LIMIT>,
						<&cpu_p04 THERMAL_NO_LIMIT THERMAL_NO_LIMIT>;
				};

				map-p1 {
					trip = <&gpu3_passive>;
					cooling-device =
						<&cpu_p10 THERMAL_NO_LIMIT THERMAL_NO_LIMIT>,
						<&cpu_p11 THERMAL_NO_LIMIT THERMAL_NO_LIMIT>,
						<&cpu_p12 THERMAL_NO_LIMIT THERMAL_NO_LIMIT>,
						<&cpu_p13 THERMAL_NO_LIMIT THERMAL_NO_LIMIT>,
						<&cpu_p14 THERMAL_NO_LIMIT THERMAL_NO_LIMIT>;
				};
			};
		};

		gpu4-thermal {
			polling-delay-passive = <1000>;
			polling-delay = <1000>;
			critical-samples = <3>;
			sustainable-power = <51300>;
			thermal-sensors = <&smc_hwmon 21>;	/* Tg0z */

			trips {
				gpu4_switch_on: trip-switch-on {
					temperature = <90000>;
					hysteresis = <2000>;
					type = "passive";
				};

				gpu4_passive: trip-passive {
					temperature = <101000>;
					hysteresis = <5000>;
					type = "passive";
				};

				trip-critical {
					temperature = <118000>;
					hysteresis = <0>;
					type = "critical";
				};
			};

			cooling-maps {
				map-e {
					trip = <&gpu4_passive>;
					cooling-device =
						<&cpu_e0 THERMAL_NO_LIMIT THERMAL_NO_LIMIT>,
						<&cpu_e1 THERMAL_NO_LIMIT THERMAL_NO_LIMIT>,
						<&cpu_e2 THERMAL_NO_LIMIT THERMAL_NO_LIMIT>,
						<&cpu_e3 THERMAL_NO_LIMIT THERMAL_NO_LIMIT>;
				};

				map-p0 {
					trip = <&gpu4_passive>;
					cooling-device =
						<&cpu_p00 THERMAL_NO_LIMIT THERMAL_NO_LIMIT>,
						<&cpu_p01 THERMAL_NO_LIMIT THERMAL_NO_LIMIT>,
						<&cpu_p02 THERMAL_NO_LIMIT THERMAL_NO_LIMIT>,
						<&cpu_p03 THERMAL_NO_LIMIT THERMAL_NO_LIMIT>,
						<&cpu_p04 THERMAL_NO_LIMIT THERMAL_NO_LIMIT>;
				};

				map-p1 {
					trip = <&gpu4_passive>;
					cooling-device =
						<&cpu_p10 THERMAL_NO_LIMIT THERMAL_NO_LIMIT>,
						<&cpu_p11 THERMAL_NO_LIMIT THERMAL_NO_LIMIT>,
						<&cpu_p12 THERMAL_NO_LIMIT THERMAL_NO_LIMIT>,
						<&cpu_p13 THERMAL_NO_LIMIT THERMAL_NO_LIMIT>,
						<&cpu_p14 THERMAL_NO_LIMIT THERMAL_NO_LIMIT>;
				};
			};
		};

		gpu5-thermal {
			polling-delay-passive = <1000>;
			polling-delay = <1000>;
			critical-samples = <3>;
			sustainable-power = <51300>;
			thermal-sensors = <&smc_hwmon 22>;	/* Tg1V */

			trips {
				gpu5_switch_on: trip-switch-on {
					temperature = <90000>;
					hysteresis = <2000>;
					type = "passive";
				};

				gpu5_passive: trip-passive {
					temperature = <101000>;
					hysteresis = <5000>;
					type = "passive";
				};

				trip-critical {
					temperature = <118000>;
					hysteresis = <0>;
					type = "critical";
				};
			};

			cooling-maps {
				map-e {
					trip = <&gpu5_passive>;
					cooling-device =
						<&cpu_e0 THERMAL_NO_LIMIT THERMAL_NO_LIMIT>,
						<&cpu_e1 THERMAL_NO_LIMIT THERMAL_NO_LIMIT>,
						<&cpu_e2 THERMAL_NO_LIMIT THERMAL_NO_LIMIT>,
						<&cpu_e3 THERMAL_NO_LIMIT THERMAL_NO_LIMIT>;
				};

				map-p0 {
					trip = <&gpu5_passive>;
					cooling-device =
						<&cpu_p00 THERMAL_NO_LIMIT THERMAL_NO_LIMIT>,
						<&cpu_p01 THERMAL_NO_LIMIT THERMAL_NO_LIMIT>,
						<&cpu_p02 THERMAL_NO_LIMIT THERMAL_NO_LIMIT>,
						<&cpu_p03 THERMAL_NO_LIMIT THERMAL_NO_LIMIT>,
						<&cpu_p04 THERMAL_NO_LIMIT THERMAL_NO_LIMIT>;
				};

				map-p1 {
					trip = <&gpu5_passive>;
					cooling-device =
						<&cpu_p10 THERMAL_NO_LIMIT THERMAL_NO_LIMIT>,
						<&cpu_p11 THERMAL_NO_LIMIT THERMAL_NO_LIMIT>,
						<&cpu_p12 THERMAL_NO_LIMIT THERMAL_NO_LIMIT>,
						<&cpu_p13 THERMAL_NO_LIMIT THERMAL_NO_LIMIT>,
						<&cpu_p14 THERMAL_NO_LIMIT THERMAL_NO_LIMIT>;
				};
			};
		};

		gpu6-thermal {
			polling-delay-passive = <1000>;
			polling-delay = <1000>;
			critical-samples = <3>;
			sustainable-power = <51300>;
			thermal-sensors = <&smc_hwmon 23>;	/* Tg1l */

			trips {
				gpu6_switch_on: trip-switch-on {
					temperature = <90000>;
					hysteresis = <2000>;
					type = "passive";
				};

				gpu6_passive: trip-passive {
					temperature = <101000>;
					hysteresis = <5000>;
					type = "passive";
				};

				trip-critical {
					temperature = <118000>;
					hysteresis = <0>;
					type = "critical";
				};
			};

			cooling-maps {
				map-e {
					trip = <&gpu6_passive>;
					cooling-device =
						<&cpu_e0 THERMAL_NO_LIMIT THERMAL_NO_LIMIT>,
						<&cpu_e1 THERMAL_NO_LIMIT THERMAL_NO_LIMIT>,
						<&cpu_e2 THERMAL_NO_LIMIT THERMAL_NO_LIMIT>,
						<&cpu_e3 THERMAL_NO_LIMIT THERMAL_NO_LIMIT>;
				};

				map-p0 {
					trip = <&gpu6_passive>;
					cooling-device =
						<&cpu_p00 THERMAL_NO_LIMIT THERMAL_NO_LIMIT>,
						<&cpu_p01 THERMAL_NO_LIMIT THERMAL_NO_LIMIT>,
						<&cpu_p02 THERMAL_NO_LIMIT THERMAL_NO_LIMIT>,
						<&cpu_p03 THERMAL_NO_LIMIT THERMAL_NO_LIMIT>,
						<&cpu_p04 THERMAL_NO_LIMIT THERMAL_NO_LIMIT>;
				};

				map-p1 {
					trip = <&gpu6_passive>;
					cooling-device =
						<&cpu_p10 THERMAL_NO_LIMIT THERMAL_NO_LIMIT>,
						<&cpu_p11 THERMAL_NO_LIMIT THERMAL_NO_LIMIT>,
						<&cpu_p12 THERMAL_NO_LIMIT THERMAL_NO_LIMIT>,
						<&cpu_p13 THERMAL_NO_LIMIT THERMAL_NO_LIMIT>,
						<&cpu_p14 THERMAL_NO_LIMIT THERMAL_NO_LIMIT>;
				};
			};
		};
	};
};

&smc_hwmon {
	/*
	 * TCMz and the 23 zone sensors after it must stay the first
	 * temperature children: the thermal zones name a sensor by its index,
	 * so the board's hwmon nodes only append after them.
	 */
	temperature-TCMz {
		apple,key-id = "TCMz";
		label = "CPU Die Max";
	};

	temperature-Tex0 {
		apple,key-id = "Tex0";
		label = "E-cluster Tex0";
	};

	temperature-Tex1 {
		apple,key-id = "Tex1";
		label = "E-cluster Tex1";
	};

	temperature-Tex2 {
		apple,key-id = "Tex2";
		label = "E-cluster Tex2";
	};

	temperature-Tex3 {
		apple,key-id = "Tex3";
		label = "E-cluster Tex3";
	};

	temperature-Tpx0 {
		apple,key-id = "Tpx0";
		label = "P-cluster Tpx0";
	};

	temperature-Tpx1 {
		apple,key-id = "Tpx1";
		label = "P-cluster Tpx1";
	};

	temperature-Tpx2 {
		apple,key-id = "Tpx2";
		label = "P-cluster Tpx2";
	};

	temperature-Tpx3 {
		apple,key-id = "Tpx3";
		label = "P-cluster Tpx3";
	};

	temperature-Tpx4 {
		apple,key-id = "Tpx4";
		label = "P-cluster Tpx4";
	};

	temperature-Tpx5 {
		apple,key-id = "Tpx5";
		label = "P-cluster Tpx5";
	};

	temperature-Tpx8 {
		apple,key-id = "Tpx8";
		label = "P-cluster Tpx8";
	};

	temperature-Tpx9 {
		apple,key-id = "Tpx9";
		label = "P-cluster Tpx9";
	};

	temperature-TpxA {
		apple,key-id = "TpxA";
		label = "P-cluster TpxA";
	};

	temperature-TpxB {
		apple,key-id = "TpxB";
		label = "P-cluster TpxB";
	};

	temperature-TpxC {
		apple,key-id = "TpxC";
		label = "P-cluster TpxC";
	};

	temperature-TpxD {
		apple,key-id = "TpxD";
		label = "P-cluster TpxD";
	};

	temperature-Tg05 {
		apple,key-id = "Tg05";
		label = "GPU Tg05";
		apple,no-data-below-millicelsius = <10000>;
	};

	temperature-Tg0S {
		apple,key-id = "Tg0S";
		label = "GPU Tg0S";
		apple,no-data-below-millicelsius = <10000>;
	};

	temperature-Tg0Y {
		apple,key-id = "Tg0Y";
		label = "GPU Tg0Y";
		apple,no-data-below-millicelsius = <10000>;
	};

	temperature-Tg0k {
		apple,key-id = "Tg0k";
		label = "GPU Tg0k";
		apple,no-data-below-millicelsius = <10000>;
	};

	temperature-Tg0z {
		apple,key-id = "Tg0z";
		label = "GPU Tg0z";
		apple,no-data-below-millicelsius = <10000>;
	};

	temperature-Tg1V {
		apple,key-id = "Tg1V";
		label = "GPU Tg1V";
		apple,no-data-below-millicelsius = <10000>;
	};

	temperature-Tg1l {
		apple,key-id = "Tg1l";
		label = "GPU Tg1l";
		apple,no-data-below-millicelsius = <10000>;
	};
};
